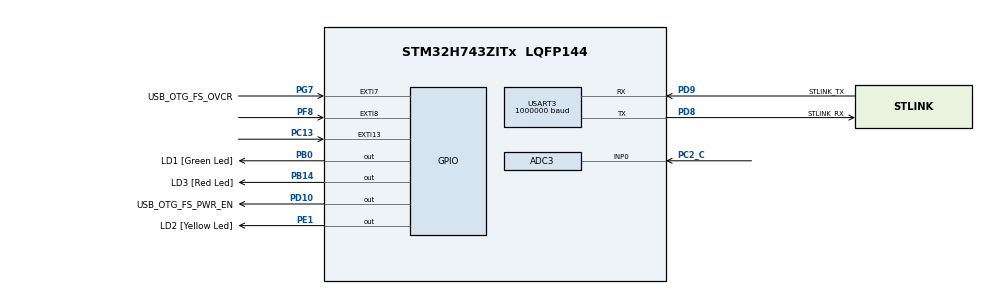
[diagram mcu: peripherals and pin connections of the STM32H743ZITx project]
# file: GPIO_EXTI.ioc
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ADC3.Channel-0\#ChannelRegularConversion=ADC_CHANNEL_0
ADC3.ExternalTrigConv=ADC_EXTERNALTRIG_T6_TRGO
ADC3.NbrOfConversionFlag=1
ADC3.OffsetNumber-0\#ChannelRegularConversion=ADC_OFFSET_NONE
ADC3.OffsetSignedSaturation-0\#ChannelRegularConversion=DISABLE
ADC3.Rank-0\#ChannelRegularConversion=1
ADC3.SamplingTime-0\#ChannelRegularConversion=ADC_SAMPLETIME_1CYCLE_5
Dma.ADC3.0.Direction=DMA_PERIPH_TO_MEMORY
Dma.ADC3.0.EventEnable=DISABLE
Dma.ADC3.0.FIFOMode=DMA_FIFOMODE_DISABLE
Dma.ADC3.0.Instance=DMA1_Stream0
Dma.ADC3.0.MemDataAlignment=DMA_MDATAALIGN_HALFWORD
Dma.ADC3.0.MemInc=DMA_MINC_ENABLE
Dma.ADC3.0.Mode=DMA_NORMAL
Dma.ADC3.0.PeriphDataAlignment=DMA_PDATAALIGN_HALFWORD
Dma.ADC3.0.PeriphInc=DMA_PINC_DISABLE
Dma.ADC3.0.Polarity=HAL_DMAMUX_REQ_GEN_RISING
Dma.ADC3.0.Priority=DMA_PRIORITY_LOW
Dma.ADC3.0.RequestNumber=1
Dma.ADC3.0.SignalID=NONE
Dma.ADC3.0.SyncEnable=DISABLE
Dma.ADC3.0.SyncPolarity=HAL_DMAMUX_SYNC_NO_EVENT
Dma.ADC3.0.SyncRequestNumber=1
Dma.ADC3.0.SyncSignalID=NONE
Dma.Request0=ADC3
Dma.Request1=USART3_TX
Dma.USART3_TX.1.Direction=DMA_MEMORY_TO_PERIPH
Dma.USART3_TX.1.EventEnable=DISABLE
Dma.USART3_TX.1.FIFOMode=DMA_FIFOMODE_DISABLE
Dma.USART3_TX.1.Instance=DMA1_Stream1
Dma.USART3_TX.1.MemDataAlignment=DMA_MDATAALIGN_BYTE
Dma.USART3_TX.1.MemInc=DMA_MINC_ENABLE
Dma.USART3_TX.1.Mode=DMA_NORMAL
Dma.USART3_TX.1.PeriphDataAlignment=DMA_PDATAALIGN_BYTE
Dma.USART3_TX.1.PeriphInc=DMA_PINC_DISABLE
Dma.USART3_TX.1.Polarity=HAL_DMAMUX_REQ_GEN_RISING
Dma.USART3_TX.1.Priority=DMA_PRIORITY_LOW
Dma.USART3_TX.1.RequestNumber=1
Dma.USART3_TX.1.SignalID=NONE
Dma.USART3_TX.1.SyncEnable=DISABLE
Dma.USART3_TX.1.SyncPolarity=HAL_DMAMUX_SYNC_NO_EVENT
Dma.USART3_TX.1.SyncRequestNumber=1
Dma.USART3_TX.1.SyncSignalID=NONE
Mcu.Family=STM32H7
Mcu.Name=STM32H743ZITx
Mcu.Package=LQFP144
NVIC.DMA1_Stream0_IRQn=true\:0\:0\:false\:false\:true\:false\:true\:true
NVIC.DMA1_Stream1_IRQn=true\:0\:0\:false\:false\:true\:false\:true\:true
NVIC.EXTI15_10_IRQn=true\:0\:0\:false\:false\:true\:true\:true\:true
NVIC.EXTI9_5_IRQn=true\:0\:0\:false\:false\:true\:true\:true\:true
NVIC.PriorityGroup=NVIC_PRIORITYGROUP_4
NVIC.USART3_IRQn=true\:0\:0\:false\:false\:true\:true\:true\:true
PA1.Signal=ETH_REF_CLK
PA11.Signal=USB_OTG_FS_DM
PA12.Signal=USB_OTG_FS_DP
PA2.Signal=ETH_MDIO
PA7.Signal=ETH_CRS_DV
PA8.Signal=USB_OTG_FS_SOF
PA9.Signal=USB_OTG_FS_VBUS
PB0.GPIO_Label=LD1 [Green Led]
PB0.Signal=GPIO_Output
PB13.Signal=ETH_TXD1
PB14.GPIO_Label=LD3 [Red Led]
PB14.Signal=GPIO_Output
PC1.Signal=ETH_MDC
PC13.GPIO_ModeDefaultEXTI=GPIO_MODE_IT_RISING
PC13.Signal=GPXTI13
PC14-OSC32_IN\ (OSC32_IN).Mode=LSE-External-Oscillator
PC14-OSC32_IN\ (OSC32_IN).Signal=RCC_OSC32_IN
PC15-OSC32_OUT\ (OSC32_OUT).Mode=LSE-External-Oscillator
PC15-OSC32_OUT\ (OSC32_OUT).Signal=RCC_OSC32_OUT
PC2_C.Mode=IN0-Single-Ended
PC2_C.Signal=ADC3_INP0
PC4.Signal=ETH_RXD0
PC5.Signal=ETH_RXD1
PD10.GPIO_Label=USB_OTG_FS_PWR_EN
PD10.Signal=GPIO_Output
PD8.GPIO_Label=STLINK_RX
PD8.Mode=Asynchronous
PD8.Signal=USART3_TX
PD9.GPIO_Label=STLINK_TX
PD9.Mode=Asynchronous
PD9.Signal=USART3_RX
PE1.GPIO_Label=LD2 [Yellow Led]
PE1.Signal=GPIO_Output
PF8.Signal=GPXTI8
PG11.Signal=ETH_TX_EN
PG13.Signal=ETH_TXD0
PG7.GPIO_Label=USB_OTG_FS_OVCR
PG7.Signal=GPXTI7
PH0-OSC_IN\ (PH0).Mode=HSE-External-Clock-Source
PH0-OSC_IN\ (PH0).Signal=RCC_OSC_IN
PH1-OSC_OUT\ (PH1).Signal=RCC_OSC_OUT
ProjectManager.HeapSize=0x200
ProjectManager.StackSize=0x400
ProjectManager.TargetToolchain=STM32CubeIDE
RCC.ADCFreq_Value=100000000
RCC.APB1Freq_Value=120000000
RCC.APB2Freq_Value=120000000
RCC.APB3Freq_Value=120000000
RCC.APB4Freq_Value=120000000
RCC.CortexFreq_Value=480000000
RCC.D1PPRE=RCC_APB3_DIV2
RCC.D2PPRE1=RCC_APB1_DIV2
RCC.D2PPRE2=RCC_APB2_DIV2
RCC.D3PPRE=RCC_APB4_DIV2
RCC.DIVM1=1
RCC.DIVM2=2
RCC.DIVN1=120
RCC.DIVN2=50
RCC.DIVQ1=4
RCC.HCLKFreq_Value=240000000
RCC.HPRE=RCC_HCLK_DIV2
RCC.HSE_VALUE=8000000
RCC.PLLFRACN=0
RCC.PLLSourceVirtual=RCC_PLLSOURCE_HSE
RCC.PWR_Regulator_Voltage_Scale=PWR_REGULATOR_VOLTAGE_SCALE0
RCC.SYSCLKFreq_VALUE=480000000
RCC.SYSCLKSource=RCC_SYSCLKSOURCE_PLLCLK
RCC.USBFreq_Value=240000000
TIM6.TIM_MasterOutputTrigger=TIM_TRGO_UPDATE
USART3.BaudRate=1000000
USART3.VirtualMode-Asynchronous=VM_ASYNC
VP_MEMORYMAP_VS_MEMORYMAP.Mode=CurAppReg
VP_TIM6_VS_ClockSourceINT.Mode=Enable_Timer
board=NUCLEO-H743ZI2

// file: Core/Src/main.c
/* USER CODE BEGIN Header */
/**
  ******************************************************************************
  * @file           : main.c
  * @brief          : Main program body
  ******************************************************************************
  * @attention
  *
  * Copyright (c) 2024 STMicroelectronics.
  * All rights reserved.
  *
  * This software is licensed under terms that can be found in the LICENSE file
  * in the root directory of this software component.
  * If no LICENSE file comes with this software, it is provided AS-IS.
  *
  ******************************************************************************
  */
/* USER CODE END Header */
#include "main.h"

/* USER CODE BEGIN Includes */

#include "Custom_ADC.h"
#include "Custom_USART.h"
#include "Custom_DMA.h"

/* USER CODE END Includes */

ADC_HandleTypeDef hadc3;
DMA_HandleTypeDef hdma_adc3;

TIM_HandleTypeDef htim6;

UART_HandleTypeDef huart3;
DMA_HandleTypeDef hdma_usart3_tx;

void SystemClock_Config(void);
static void MX_GPIO_Init(void);
static void MX_DMA_Init(void);
static void MX_ADC3_Init(void);
static void MX_USART3_UART_Init(void);
static void MX_TIM6_Init(void);

int main(void)
{

  /* MCU Configuration--------------------------------------------------------*/

  /* Reset of all peripherals, Initializes the Flash interface and the Systick. */
  HAL_Init();

  /* Configure the system clock */
  SystemClock_Config();

  /* Initialize all configured peripherals */
  MX_GPIO_Init();
  MX_DMA_Init();
  MX_ADC3_Init();
  MX_USART3_UART_Init();
  MX_TIM6_Init();
  /* USER CODE BEGIN 2 */

  ADC_custom_init();
  USART_custom_init();
  DMA_custom_init();

  /* USER CODE END 2 */

  /* Infinite loop */
  while (1)
  {

  }
}

void SystemClock_Config(void)
{
  RCC_OscInitTypeDef RCC_OscInitStruct = {0};
  RCC_ClkInitTypeDef RCC_ClkInitStruct = {0};

  /** Supply configuration update enable
  */
  HAL_PWREx_ConfigSupply(PWR_LDO_SUPPLY);

  /** Configure the main internal regulator output voltage
  */
  __HAL_PWR_VOLTAGESCALING_CONFIG(PWR_REGULATOR_VOLTAGE_SCALE1);

  while(!__HAL_PWR_GET_FLAG(PWR_FLAG_VOSRDY)) {}

  __HAL_RCC_SYSCFG_CLK_ENABLE();
  __HAL_PWR_VOLTAGESCALING_CONFIG(PWR_REGULATOR_VOLTAGE_SCALE0);

  while(!__HAL_PWR_GET_FLAG(PWR_FLAG_VOSRDY)) {}

  /** Initializes the RCC Oscillators according to the specified parameters
  * in the RCC_OscInitTypeDef structure.
  */
  RCC_OscInitStruct.OscillatorType = RCC_OSCILLATORTYPE_HSE;
  RCC_OscInitStruct.HSEState = RCC_HSE_BYPASS;
  RCC_OscInitStruct.PLL.PLLState = RCC_PLL_ON;
  RCC_OscInitStruct.PLL.PLLSource = RCC_PLLSOURCE_HSE;
  RCC_OscInitStruct.PLL.PLLM = 1;
  RCC_OscInitStruct.PLL.PLLN = 120;
  RCC_OscInitStruct.PLL.PLLP = 2;
  RCC_OscInitStruct.PLL.PLLQ = 4;
  RCC_OscInitStruct.PLL.PLLR = 2;
  RCC_OscInitStruct.PLL.PLLRGE = RCC_PLL1VCIRANGE_3;
  RCC_OscInitStruct.PLL.PLLVCOSEL = RCC_PLL1VCOWIDE;
  RCC_OscInitStruct.PLL.PLLFRACN = 0;
  if (HAL_RCC_OscConfig(&RCC_OscInitStruct) != HAL_OK)
  {
    Error_Handler();
  }

  /** Initializes the CPU, AHB and APB buses clocks
  */
  RCC_ClkInitStruct.ClockType = RCC_CLOCKTYPE_HCLK|RCC_CLOCKTYPE_SYSCLK
                              |RCC_CLOCKTYPE_PCLK1|RCC_CLOCKTYPE_PCLK2
                              |RCC_CLOCKTYPE_D3PCLK1|RCC_CLOCKTYPE_D1PCLK1;
  RCC_ClkInitStruct.SYSCLKSource = RCC_SYSCLKSOURCE_PLLCLK;
  RCC_ClkInitStruct.SYSCLKDivider = RCC_SYSCLK_DIV1;
  RCC_ClkInitStruct.AHBCLKDivider = RCC_HCLK_DIV2;
  RCC_ClkInitStruct.APB3CLKDivider = RCC_APB3_DIV2;
  RCC_ClkInitStruct.APB1CLKDivider = RCC_APB1_DIV2;
  RCC_ClkInitStruct.APB2CLKDivider = RCC_APB2_DIV2;
  RCC_ClkInitStruct.APB4CLKDivider = RCC_APB4_DIV2;

  if (HAL_RCC_ClockConfig(&RCC_ClkInitStruct, FLASH_LATENCY_4) != HAL_OK)
  {
    Error_Handler();
  }
}

static void MX_ADC3_Init(void)
{

  ADC_ChannelConfTypeDef sConfig = {0};

  /** Common config
  */
  hadc3.Instance = ADC3;
  hadc3.Init.ClockPrescaler = ADC_CLOCK_ASYNC_DIV1;
  hadc3.Init.ScanConvMode = ADC_SCAN_DISABLE;
  hadc3.Init.EOCSelection = ADC_EOC_SINGLE_CONV;
  hadc3.Init.LowPowerAutoWait = DISABLE;
  hadc3.Init.ContinuousConvMode = DISABLE;
  hadc3.Init.NbrOfConversion = 1;
  hadc3.Init.DiscontinuousConvMode = DISABLE;
  hadc3.Init.ExternalTrigConv = ADC_EXTERNALTRIG_T6_TRGO;
  hadc3.Init.ExternalTrigConvEdge = ADC_EXTERNALTRIGCONVEDGE_RISING;
  hadc3.Init.ConversionDataManagement = ADC_CONVERSIONDATA_DR;
  hadc3.Init.Overrun = ADC_OVR_DATA_PRESERVED;
  hadc3.Init.LeftBitShift = ADC_LEFTBITSHIFT_NONE;
  hadc3.Init.OversamplingMode = DISABLE;
  hadc3.Init.Oversampling.Ratio = 1;
  if (HAL_ADC_Init(&hadc3) != HAL_OK)
  {
    Error_Handler();
  }
  hadc3.Init.Resolution = ADC_RESOLUTION_16B;
  if (HAL_ADC_Init(&hadc3) != HAL_OK)
  {
    Error_Handler();
  }

  /** Configure Regular Channel
  */
  sConfig.Channel = ADC_CHANNEL_0;
  sConfig.Rank = ADC_REGULAR_RANK_1;
  sConfig.SamplingTime = ADC_SAMPLETIME_1CYCLE_5;
  sConfig.SingleDiff = ADC_SINGLE_ENDED;
  sConfig.OffsetNumber = ADC_OFFSET_NONE;
  sConfig.Offset = 0;
  sConfig.OffsetSignedSaturation = DISABLE;
  if (HAL_ADC_ConfigChannel(&hadc3, &sConfig) != HAL_OK)
  {
    Error_Handler();
  }

}

static void MX_TIM6_Init(void)
{

  TIM_MasterConfigTypeDef sMasterConfig = {0};

  htim6.Instance = TIM6;
  htim6.Init.Prescaler = 0;
  htim6.Init.CounterMode = TIM_COUNTERMODE_UP;
  htim6.Init.Period = 65535;
  htim6.Init.AutoReloadPreload = TIM_AUTORELOAD_PRELOAD_DISABLE;
  if (HAL_TIM_Base_Init(&htim6) != HAL_OK)
  {
    Error_Handler();
  }
  sMasterConfig.MasterOutputTrigger = TIM_TRGO_UPDATE;
  sMasterConfig.MasterSlaveMode = TIM_MASTERSLAVEMODE_DISABLE;
  if (HAL_TIMEx_MasterConfigSynchronization(&htim6, &sMasterConfig) != HAL_OK)
  {
    Error_Handler();
  }

}

static void MX_USART3_UART_Init(void)
{

  huart3.Instance = USART3;
  huart3.Init.BaudRate = 1000000;
  huart3.Init.WordLength = UART_WORDLENGTH_8B;
  huart3.Init.StopBits = UART_STOPBITS_1;
  huart3.Init.Parity = UART_PARITY_NONE;
  huart3.Init.Mode = UART_MODE_TX_RX;
  huart3.Init.HwFlowCtl = UART_HWCONTROL_NONE;
  huart3.Init.OverSampling = UART_OVERSAMPLING_16;
  huart3.Init.OneBitSampling = UART_ONE_BIT_SAMPLE_DISABLE;
  huart3.Init.ClockPrescaler = UART_PRESCALER_DIV1;
  huart3.AdvancedInit.AdvFeatureInit = UART_ADVFEATURE_NO_INIT;
  if (HAL_UART_Init(&huart3) != HAL_OK)
  {
    Error_Handler();
  }
  if (HAL_UARTEx_SetTxFifoThreshold(&huart3, UART_TXFIFO_THRESHOLD_1_8) != HAL_OK)
  {
    Error_Handler();
  }
  if (HAL_UARTEx_SetRxFifoThreshold(&huart3, UART_RXFIFO_THRESHOLD_1_8) != HAL_OK)
  {
    Error_Handler();
  }
  if (HAL_UARTEx_DisableFifoMode(&huart3) != HAL_OK)
  {
    Error_Handler();
  }

}

static void MX_DMA_Init(void)
{

  /* DMA controller clock enable */
  __HAL_RCC_DMA1_CLK_ENABLE();

  /* DMA interrupt init */
  /* DMA1_Stream0_IRQn interrupt configuration */
  HAL_NVIC_SetPriority(DMA1_Stream0_IRQn, 0, 0);
  HAL_NVIC_EnableIRQ(DMA1_Stream0_IRQn);
  /* DMA1_Stream1_IRQn interrupt configuration */
  HAL_NVIC_SetPriority(DMA1_Stream1_IRQn, 0, 0);
  HAL_NVIC_EnableIRQ(DMA1_Stream1_IRQn);

}

static void MX_GPIO_Init(void)
{
  GPIO_InitTypeDef GPIO_InitStruct = {0};

  /* GPIO Ports Clock Enable */
  __HAL_RCC_GPIOC_CLK_ENABLE();
  __HAL_RCC_GPIOF_CLK_ENABLE();
  __HAL_RCC_GPIOH_CLK_ENABLE();
  __HAL_RCC_GPIOA_CLK_ENABLE();
  __HAL_RCC_GPIOB_CLK_ENABLE();
  __HAL_RCC_GPIOD_CLK_ENABLE();
  __HAL_RCC_GPIOG_CLK_ENABLE();
  __HAL_RCC_GPIOE_CLK_ENABLE();

  /*Configure GPIO pin Output Level */
  HAL_GPIO_WritePin(GPIOB, LD1_Pin|LD3_Pin, GPIO_PIN_RESET);

  /*Configure GPIO pin Output Level */
  HAL_GPIO_WritePin(USB_OTG_FS_PWR_EN_GPIO_Port, USB_OTG_FS_PWR_EN_Pin, GPIO_PIN_RESET);

  /*Configure GPIO pin Output Level */
  HAL_GPIO_WritePin(LD2_GPIO_Port, LD2_Pin, GPIO_PIN_RESET);

  /*Configure GPIO pin : PC13 */
  GPIO_InitStruct.Pin = GPIO_PIN_13;
  GPIO_InitStruct.Mode = GPIO_MODE_IT_RISING;
  GPIO_InitStruct.Pull = GPIO_NOPULL;
  HAL_GPIO_Init(GPIOC, &GPIO_InitStruct);

  /*Configure GPIO pin : PF8 */
  GPIO_InitStruct.Pin = GPIO_PIN_8;
  GPIO_InitStruct.Mode = GPIO_MODE_IT_RISING;
  GPIO_InitStruct.Pull = GPIO_NOPULL;
  HAL_GPIO_Init(GPIOF, &GPIO_InitStruct);

  /*Configure GPIO pins : PC1 PC4 PC5 */
  GPIO_InitStruct.Pin = GPIO_PIN_1|GPIO_PIN_4|GPIO_PIN_5;
  GPIO_InitStruct.Mode = GPIO_MODE_AF_PP;
  GPIO_InitStruct.Pull = GPIO_NOPULL;
  GPIO_InitStruct.Speed = GPIO_SPEED_FREQ_LOW;
  GPIO_InitStruct.Alternate = GPIO_AF11_ETH;
  HAL_GPIO_Init(GPIOC, &GPIO_InitStruct);

  /*Configure GPIO pins : PA1 PA2 PA7 */
  GPIO_InitStruct.Pin = GPIO_PIN_1|GPIO_PIN_2|GPIO_PIN_7;
  GPIO_InitStruct.Mode = GPIO_MODE_AF_PP;
  GPIO_InitStruct.Pull = GPIO_NOPULL;
  GPIO_InitStruct.Speed = GPIO_SPEED_FREQ_LOW;
  GPIO_InitStruct.Alternate = GPIO_AF11_ETH;
  HAL_GPIO_Init(GPIOA, &GPIO_InitStruct);

  /*Configure GPIO pins : LD1_Pin LD3_Pin */
  GPIO_InitStruct.Pin = LD1_Pin|LD3_Pin;
  GPIO_InitStruct.Mode = GPIO_MODE_OUTPUT_PP;
  GPIO_InitStruct.Pull = GPIO_NOPULL;
  GPIO_InitStruct.Speed = GPIO_SPEED_FREQ_LOW;
  HAL_GPIO_Init(GPIOB, &GPIO_InitStruct);

  /*Configure GPIO pin : PB13 */
  GPIO_InitStruct.Pin = GPIO_PIN_13;
  GPIO_InitStruct.Mode = GPIO_MODE_AF_PP;
  GPIO_InitStruct.Pull = GPIO_NOPULL;
  GPIO_InitStruct.Speed = GPIO_SPEED_FREQ_LOW;
  GPIO_InitStruct.Alternate = GPIO_AF11_ETH;
  HAL_GPIO_Init(GPIOB, &GPIO_InitStruct);

  /*Configure GPIO pin : USB_OTG_FS_PWR_EN_Pin */
  GPIO_InitStruct.Pin = USB_OTG_FS_PWR_EN_Pin;
  GPIO_InitStruct.Mode = GPIO_MODE_OUTPUT_PP;
  GPIO_InitStruct.Pull = GPIO_NOPULL;
  GPIO_InitStruct.Speed = GPIO_SPEED_FREQ_LOW;
  HAL_GPIO_Init(USB_OTG_FS_PWR_EN_GPIO_Port, &GPIO_InitStruct);

  /*Configure GPIO pin : USB_OTG_FS_OVCR_Pin */
  GPIO_InitStruct.Pin = USB_OTG_FS_OVCR_Pin;
  GPIO_InitStruct.Mode = GPIO_MODE_IT_RISING;
  GPIO_InitStruct.Pull = GPIO_NOPULL;
  HAL_GPIO_Init(USB_OTG_FS_OVCR_GPIO_Port, &GPIO_InitStruct);

  /*Configure GPIO pins : PA8 PA11 PA12 */
  GPIO_InitStruct.Pin = GPIO_PIN_8|GPIO_PIN_11|GPIO_PIN_12;
  GPIO_InitStruct.Mode = GPIO_MODE_AF_PP;
  GPIO_InitStruct.Pull = GPIO_NOPULL;
  GPIO_InitStruct.Speed = GPIO_SPEED_FREQ_LOW;
  GPIO_InitStruct.Alternate = GPIO_AF10_OTG1_FS;
  HAL_GPIO_Init(GPIOA, &GPIO_InitStruct);

  /*Configure GPIO pins : PG11 PG13 */
  GPIO_InitStruct.Pin = GPIO_PIN_11|GPIO_PIN_13;
  GPIO_InitStruct.Mode = GPIO_MODE_AF_PP;
  GPIO_InitStruct.Pull = GPIO_NOPULL;
  GPIO_InitStruct.Speed = GPIO_SPEED_FREQ_LOW;
  GPIO_InitStruct.Alternate = GPIO_AF11_ETH;
  HAL_GPIO_Init(GPIOG, &GPIO_InitStruct);

  /*Configure GPIO pin : LD2_Pin */
  GPIO_InitStruct.Pin = LD2_Pin;
  GPIO_InitStruct.Mode = GPIO_MODE_OUTPUT_PP;
  GPIO_InitStruct.Pull = GPIO_NOPULL;
  GPIO_InitStruct.Speed = GPIO_SPEED_FREQ_LOW;
  HAL_GPIO_Init(LD2_GPIO_Port, &GPIO_InitStruct);

  /* EXTI interrupt init*/
  HAL_NVIC_SetPriority(EXTI9_5_IRQn, 0, 0);
  HAL_NVIC_EnableIRQ(EXTI9_5_IRQn);

  HAL_NVIC_SetPriority(EXTI15_10_IRQn, 0, 0);
  HAL_NVIC_EnableIRQ(EXTI15_10_IRQn);

}

void Error_Handler(void)
{
  __disable_irq();
  while (1)
  {
  }
}
